# PIC18F56Q71 register map
Vendor: Microchip
Registers are 8-bit, read-write, reset 0x0 unless marked. A register's access mark holds for its fields unless they carry their own. Addresses are absolute, and some are shared; only a register's first bit layout is shown; [hi:lo] are bit positions; {n}, {i} and the like mark numbered series.

## math_progcrc
0x34E CRCDATAL
  [7:0] DATA
0x34F CRCDATAH
  [7:0] DATA
0x350 CRCDATAU
  [7:0] DATA
0x351 CRCDATAT
  [7:0] DATA
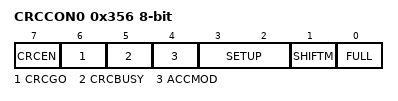
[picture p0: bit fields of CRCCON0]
0x356 CRCCON0
  [7] CRCEN, [6] CRCGO, [5] CRCBUSY ro, [4] ACCMOD, [3:2] SETUP, [1] SHIFTM, [0] FULL ro
0x357 CRCCON1
  [4:0] PLEN
0x358 CRCCON2
  [4:0] DLEN

## nvm_scan
0x35A SCANLADRL
  [7:0] LADR
0x35B SCANLADRH
  [7:0] LADR
0x35C SCANLADRU
  [5:0] LADR
0x35D SCANHADRL reset 0xFF
  [7:0] HADR
0x35E SCANHADRH reset 0xFF
  [7:0] HADR
0x35F SCANHADRU reset 0x3F
  [5:0] HADR
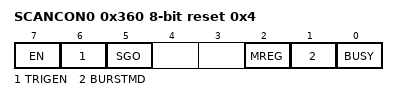
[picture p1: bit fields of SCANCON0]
0x360 SCANCON0 reset 0x4
  [7] EN, [6] TRIGEN, [5] SGO, [2] MREG, [1] BURSTMD, [0] BUSY
0x361 SCANTRIG
  [4:0] TSEL

## wg_ecwg
0x3BC CWG1CLK
  [0] CS
0x3BD CWG1ISM
  [4:0] ISM
0x3BE CWG1DBR
  [5:0] DBR
0x3BF CWG1DBF
  [5:0] DBF
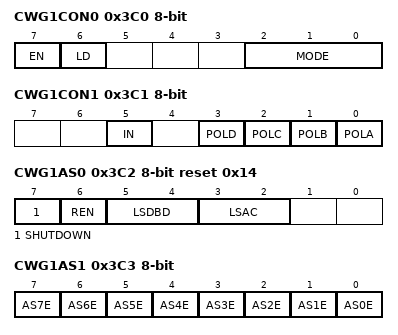
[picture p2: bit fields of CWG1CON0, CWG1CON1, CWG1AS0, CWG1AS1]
0x3C0 CWG1CON0
  [7] EN, [6] LD, [2:0] MODE
0x3C1 CWG1CON1 reset not defined — (power-on value --x-0000)
  [5] IN ro, [3] POLD, [2] POLC, [1] POLB, [0] POLA
0x3C2 CWG1AS0 reset 0x14
  [7] SHUTDOWN, [6] REN, [5:4] LSDBD, [3:2] LSAC
0x3C3 CWG1AS1
  [n] AS{n}E (n=0..7)
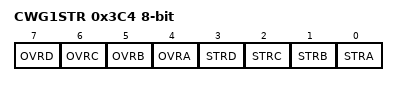
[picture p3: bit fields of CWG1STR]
0x3C4 CWG1STR
  [7] OVRD, [6] OVRC, [5] OVRB, [4] OVRA, [3] STRD, [2] STRC, [1] STRB, [0] STRA

## amp_fvr_ts_ctrl
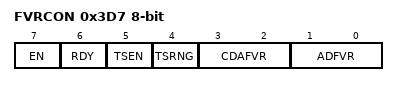
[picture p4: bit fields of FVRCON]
0x3D7 FVRCON reset not defined — (power-on value xx000000)
  [7] EN — Zero-Cross Detect Software Enable bit
  [6] RDY ro
  [5] TSEN — Zero-Cross Detect Data Output
  [4] TSRNG — Zero-Cross Detect Polarity bit
  [3:2] CDAFVR
  [1:0] ADFVR — Zero-Cross Detect Positive-going Edge Interrupt Enable

## adc_sarcore_mp_ctrl
0x3D9 ADLTHL
  [7:0] LTH
0x3DA ADLTHH
  [7:0] LTH
0x3DB ADUTHL
  [7:0] UTH
0x3DC ADUTHH
  [7:0] UTH
0x3DD ADERRL ro reset not defined — (power-on value xxxxxxxx)
  [7:0] ERR
0x3DE ADERRH ro reset not defined — (power-on value xxxxxxxx)
  [7:0] ERR
0x3DF ADSTPTL
  [7:0] STPT
0x3E0 ADSTPTH
  [7:0] STPT
0x3E1 ADFLTRL ro reset not defined — (power-on value xxxxxxxx)
  [7:0] FLTR
0x3E2 ADFLTRH ro reset not defined — (power-on value xxxxxxxx)
  [7:0] FLTR
0x3E3 ADACCL reset not defined — (power-on value xxxxxxxx)
  [7:0] ACC
0x3E4 ADACCH reset not defined — (power-on value xxxxxxxx)
  [7:0] ACC
0x3E5 ADACCU reset not defined — (power-on value ------xx)
  [1:0] ACC
0x3E6 ADCNT reset not defined — (power-on value xxxxxxxx)
  [7:0] CNT
0x3E7 ADRPT
  [7:0] RPT
0x3E8 ADPREVL ro reset not defined — (power-on value xxxxxxxx)
  [7:0] PREV
0x3E9 ADPREVH ro reset not defined — (power-on value xxxxxxxx)
  [7:0] PREV
0x3EA ADRESL
  [7:0] RES
0x3EB ADRESH
  [7:0] RES
0x3EC ADPCH reset not defined — (power-on value xxxxxxxx)
  [7:0] PCH
0x3ED ADNCH
  [5:0] ADNCH
0x3EE ADACQL
  [7:0] ACQ
0x3EF ADACQH
  [4:0] ACQ
0x3F0 ADCAP
  [4:0] ADCAP
0x3F1 ADPREL
  [7:0] PRE
0x3F2 ADPREH
  [4:0] PRE
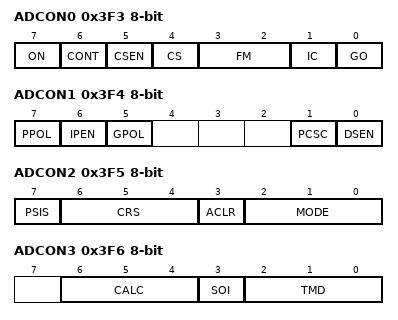
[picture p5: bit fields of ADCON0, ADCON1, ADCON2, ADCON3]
0x3F3 ADCON0 reset not defined — (power-on value 00x00010)
  [7] ON, [6] CONT, [5] CSEN, [4] CS, [3:2] FM, [1] IC, [0] GO
0x3F4 ADCON1 reset not defined — (power-on value 000---x0)
  [7] PPOL, [6] IPEN, [5] GPOL, [1] PCSC, [0] DSEN
0x3F5 ADCON2
  [7] PSIS, [6:4] CRS, [3] ACLR, [2:0] MODE
0x3F6 ADCON3
  [6:4] CALC, [3] SOI, [2:0] TMD
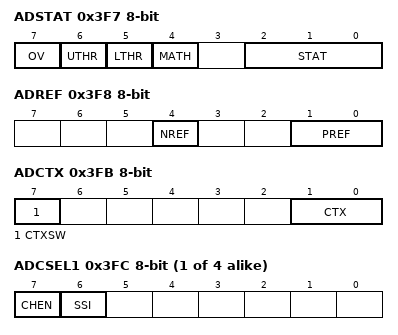
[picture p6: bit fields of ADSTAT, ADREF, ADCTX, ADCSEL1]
0x3F7 ADSTAT
  [7] OV ro
  [6] UTHR ro
  [5] LTHR ro
  [4] MATH — (can only be cleared)
  [2:0] STAT ro
0x3F8 ADREF
  [4] NREF, [1:0] PREF
0x3F9 ADACT
  [5:0] ACT
0x3FA ADCLK
  [5:0] CS
0x3FB ADCTX
  [7] CTXSW, [1:0] CTX
{0x3FB+i} ADCSEL{i} reset not defined (i=1..4) — (power-on value 0x------)
  [7] CHEN, [6] SSI

## DOS_xxxxx_port_control
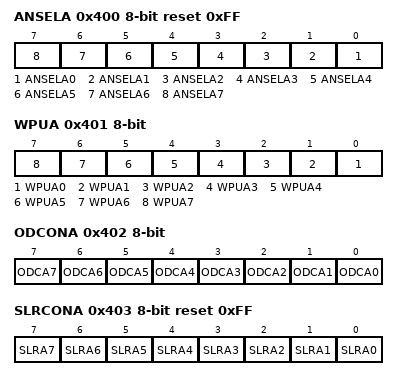
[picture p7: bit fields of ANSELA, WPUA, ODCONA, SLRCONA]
0x400 ANSELA reset 0xFF
  [n] ANSELA{n} (n=0..7)
0x401 WPUA
  [n] WPUA{n} (n=0..7)
0x402 ODCONA
  [n] ODCA{n} (n=0..7)
0x403 SLRCONA reset 0xFF
  [n] SLRA{n} (n=0..7)
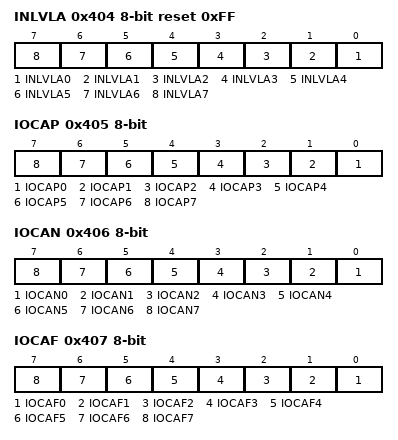
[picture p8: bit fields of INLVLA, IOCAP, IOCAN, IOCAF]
0x404 INLVLA reset 0xFF
  [n] INLVLA{n} (n=0..7)
0x405 IOCAP
  [n] IOCAP{n} (n=0..7)
0x406 IOCAN
  [n] IOCAN{n} (n=0..7)
0x407 IOCAF
  [n] IOCAF{n} (n=0..7)
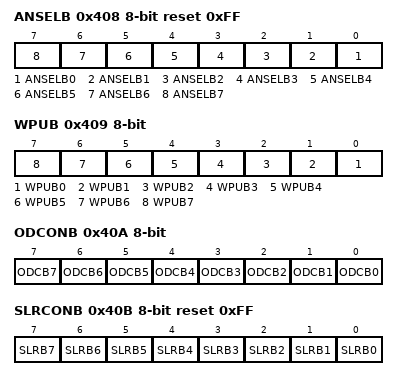
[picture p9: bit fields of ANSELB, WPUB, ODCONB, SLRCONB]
0x408 ANSELB reset 0xFF
  [n] ANSELB{n} (n=0..7)
0x409 WPUB
  [n] WPUB{n} (n=0..7)
0x40A ODCONB
  [n] ODCB{n} (n=0..7)
0x40B SLRCONB reset 0xFF
  [n] SLRB{n} (n=0..7)
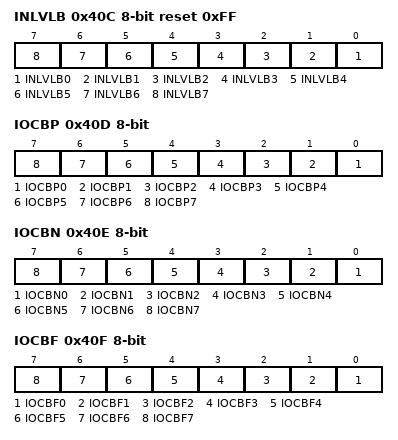
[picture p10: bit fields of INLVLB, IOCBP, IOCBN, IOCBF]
0x40C INLVLB reset 0xFF
  [n] INLVLB{n} (n=0..7)
0x40D IOCBP
  [n] IOCBP{n} (n=0..7)
0x40E IOCBN
  [n] IOCBN{n} (n=0..7)
0x40F IOCBF
  [n] IOCBF{n} (n=0..7)
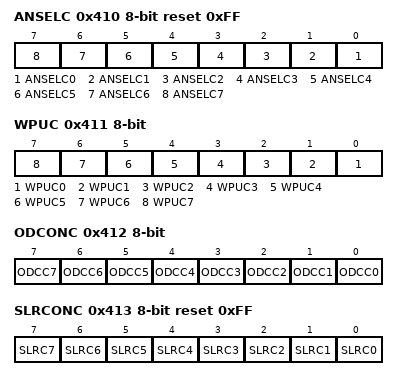
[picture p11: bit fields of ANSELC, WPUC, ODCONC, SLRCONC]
0x410 ANSELC reset 0xFF
  [n] ANSELC{n} (n=0..7)
0x411 WPUC
  [n] WPUC{n} (n=0..7)
0x412 ODCONC
  [n] ODCC{n} (n=0..7)
0x413 SLRCONC reset 0xFF
  [n] SLRC{n} (n=0..7)
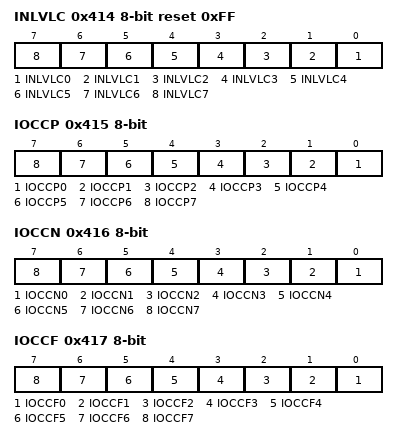
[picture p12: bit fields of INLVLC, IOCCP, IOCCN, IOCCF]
0x414 INLVLC reset 0xFF
  [n] INLVLC{n} (n=0..7)
0x415 IOCCP
  [n] IOCCP{n} (n=0..7)
0x416 IOCCN
  [n] IOCCN{n} (n=0..7)
0x417 IOCCF
  [n] IOCCF{n} (n=0..7)
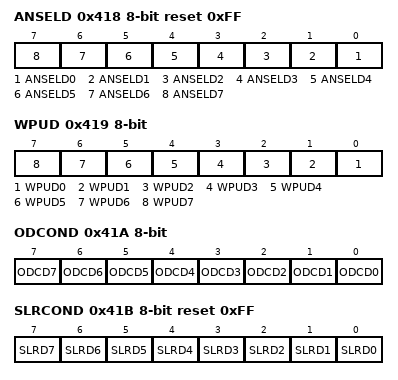
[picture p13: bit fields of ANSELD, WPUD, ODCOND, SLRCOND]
0x418 ANSELD reset 0xFF
  [n] ANSELD{n} (n=0..7)
0x419 WPUD
  [n] WPUD{n} (n=0..7)
0x41A ODCOND
  [n] ODCD{n} (n=0..7)
0x41B SLRCOND reset 0xFF
  [n] SLRD{n} (n=0..7)
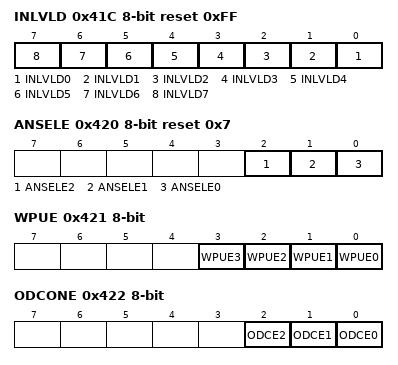
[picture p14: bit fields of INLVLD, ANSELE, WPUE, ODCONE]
0x41C INLVLD reset 0xFF
  [n] INLVLD{n} (n=0..7)
0x420 ANSELE reset 0x7
  [2] ANSELE2, [1] ANSELE1, [0] ANSELE0
0x421 WPUE
  [n] WPUE{n} (n=0..3)
0x422 ODCONE
  [2] ODCE2, [1] ODCE1, [0] ODCE0
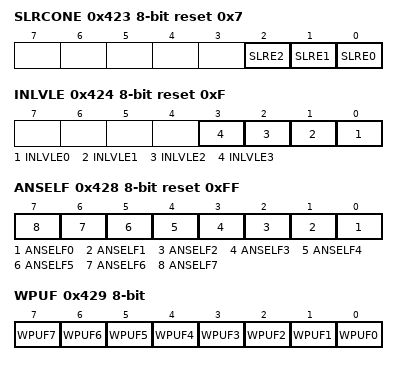
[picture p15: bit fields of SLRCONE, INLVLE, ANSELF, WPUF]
0x423 SLRCONE reset 0x7
  [2] SLRE2, [1] SLRE1, [0] SLRE0
0x424 INLVLE reset 0xF
  [n] INLVLE{n} (n=0..3)
0x425 IOCEP
  [3] IOCEP3
0x426 IOCEN
  [3] IOCEN3
0x427 IOCEF
  [3] IOCEF3
0x428 ANSELF reset 0xFF
  [n] ANSELF{n} (n=0..7)
0x429 WPUF
  [n] WPUF{n} (n=0..7)
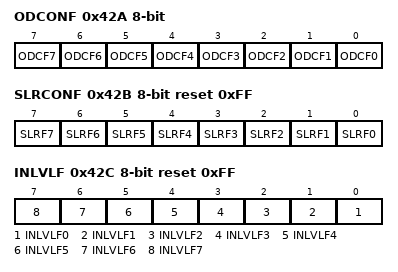
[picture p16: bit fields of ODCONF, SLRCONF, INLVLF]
0x42A ODCONF
  [n] ODCF{n} (n=0..7)
0x42B SLRCONF reset 0xFF
  [n] SLRF{n} (n=0..7)
0x42C INLVLF reset 0xFF
  [n] INLVLF{n} (n=0..7)
